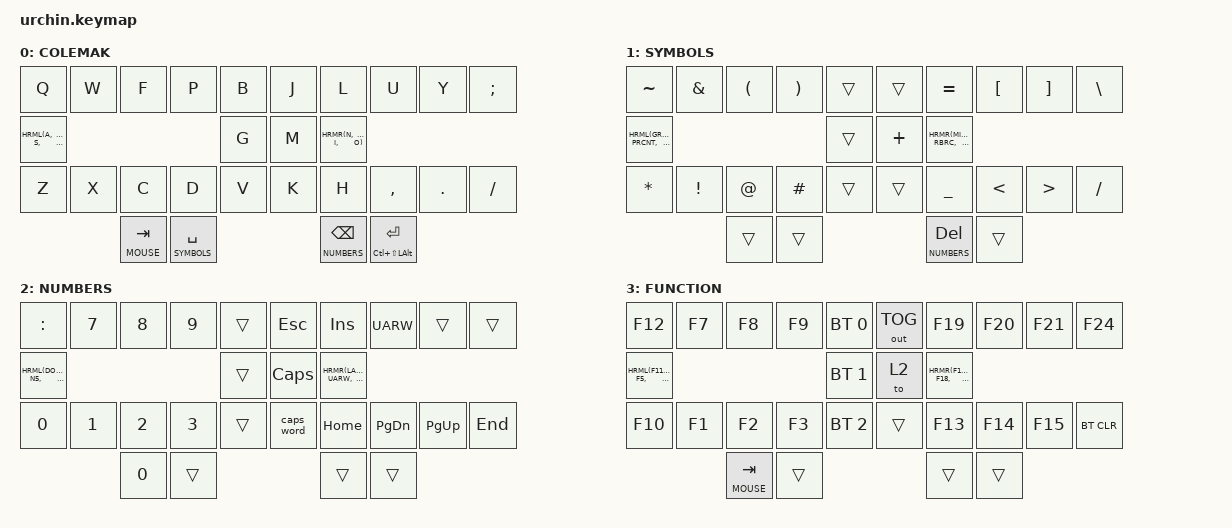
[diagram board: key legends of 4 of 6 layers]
// TODO
// add macro to accelerate or teleport mouse in each directions

#include <behaviors.dtsi>
#include <dt-bindings/zmk/keys.h>
#include <dt-bindings/zmk/bt.h>
#include <dt-bindings/zmk/outputs.h>

#include <dt-bindings/zmk/mouse.h> 
#include <behaviors.dtsi>

// Home row mods macro
#define HRML(k1,k2,k3,k4) &ht LSHFT k1  &ht LCTRL k2  &ht LALT k3  &ht LGUI k4
#define HRMR(k1,k2,k3,k4) &ht RGUI k1  &ht RALT k2  &ht RCTRL k3  &ht RSHFT k4

#define COLEMAK 0
#define SYMBOLS 1
#define NUMBERS 2
#define FUNCTIONS 3
#define MOUSE 4
#define GAME 5

#define U_MOUSE_MOVE_MAX 2000                     /* <--- New max speed setting (default: 600) */
#undef MOVE_UP
#undef MOVE_DOWN
#undef MOVE_LEFT
#undef MOVE_RIGHT
#define MOVE_UP MOVE_Y(-U_MOUSE_MOVE_MAX)
#define MOVE_DOWN MOVE_Y(U_MOUSE_MOVE_MAX)
#define MOVE_LEFT MOVE_X(-U_MOUSE_MOVE_MAX)
#define MOVE_RIGHT MOVE_X(U_MOUSE_MOVE_MAX)

&mmv {
 	time-to-max-speed-ms = <500>;             /* <--- How long time until max speed is reached (default: 500) */
};

#define U_MOUSE_SCROLL_MAX 100                    /* <--- New max speed setting (default: 10) */

#undef SCROLL_UP
#undef SCROLL_DOWN
#undef SCROLL_LEFT
#undef SCROLL_RIGHT
#define SCROLL_UP SCROLL_Y(U_MOUSE_SCROLL_MAX)
#define SCROLL_DOWN SCROLL_Y(-U_MOUSE_SCROLL_MAX)
#define SCROLL_LEFT SCROLL_X(-U_MOUSE_SCROLL_MAX)
#define SCROLL_RIGHT SCROLL_X(U_MOUSE_SCROLL_MAX)

&msc {
  time-to-max-speed-ms = <500>;                 /* <--- How long time until max speed is reached */
};

/ {
    behaviors {
        //ht: hold_tap {
        //    compatible = "zmk,behavior-hold-tap";
        //    #binding-cells = <2>;
        //    flavor = "balanced";
        //    tapping-term-ms = <220>;
        //    quick-tap-ms = <150>;
        //    require-prior-idle-ms = <100>;
        //    bindings = <&kp>, <&kp>;
        //};

        ht: hold_tap {
            compatible = "zmk,behavior-hold-tap";
            #binding-cells = <2>;
            flavor = "tap-preferred";
            tapping-term-ms = <180>;
            quick-tap-ms = <180>;
            require-prior-idle-ms = <100>;
            bindings = <&kp>, <&kp>;
        };

        //ht: hold_tap {
        //    compatible = "zmk,behavior-hold-tap";
        //    #binding-cells = <2>;
        //    flavor = "tap-unless-interrupted";
        //    tapping-term-ms = <200>;
        //    quick-tap-ms = <150>;
        //    require-prior-idle-ms = <100>;
        //    bindings = <&kp>, <&kp>;
        //};

    };

    combos {
        compatible = "zmk,combos"; 

        function_layer_combo {
            bindings = <&mo FUNCTIONS>;
            key-positions = <30 33>; //inner thumb keys
            timeout-ms = <50>;
        };

        game_layer_combo {
            bindings = <&tog GAME>;
            key-positions = <0 1 2 3>;
            timeout-ms = <50>;
        };

        repeat_key_combo_right {
            bindings = <&key_repeat>;
            key-positions = <26 27>; //bottom right index and middle finger keys
            timeout-ms = <50>;
        };

        repeat_key_combo_left {
            bindings = <&key_repeat>;
            key-positions = <22 23>; //bottom right index and middle finger keys
            timeout-ms = <50>;
        };

    };

    conditional_layers {
        compatible = "zmk,conditional-layers";
        tri_layer {
            if-layers = <SYMBOLS NUMBERS>;
            then-layer = <FUNCTIONS>;
        };
    };

    ZMK_MACRO(hyper_key,
        wait-ms = <0>;
        tap-ms = <40>;
        bindings = <&kp LSHFT &kp LCTRL &kp LALT &kp LGUI>;
    )

    keymap {
        compatible = "zmk,keymap";
        colemak_layer {
            label = "COLEMAK";
            bindings = <
        //╭──────────┬──────────┬──────────┬──────────┬──────────╮   ╭──────────┬──────────┬──────────┬──────────┬──────────╮
        //│  Q       │  W       │  F       │  P       │  B       │   │  J       │  L       │  U       │  Y       │  ; :     │
            &kp Q      &kp W      &kp F      &kp P      &kp B          &kp J      &kp L      &kp U      &kp Y      &kp SEMI
        //├──────────┼──────────┼──────────┼──────────┼──────────┤   ├──────────┼──────────┼──────────┼──────────┼──────────┤
        //│  A       │  R       │  S       │  T       │  G       │   │  M       │  N       │  E       │  I       │  O       │
            HRML(A,        R,         S,         T)     &kp G          &kp M      HRMR(N,        E,         I,        O)
        //├──────────┼──────────┼──────────┼──────────┼──────────┤   ├──────────┼──────────┼──────────┼──────────┼──────────┤
        //│  Z       │  X       │  C       │  D       │  V       │   │  K       │  H       │ , <      │ . >      │ / ?      │
            &kp Z      &kp X      &kp C      &kp D      &kp V          &kp K      &kp H      &kp COMMA  &kp DOT    &kp FSLH
        //╰──────────┴──────────┴──────────┼──────────┼──────────┤   ├──────────┼──────────┼──────────┴──────────┴──────────╯
                                  &lt MOUSE TAB   &lt SYMBOLS SPACE    &lt NUMBERS BSPC    &mt LC(LS(LALT)) ENTER 
        //                                 ╰──────────┴──────────╯   ╰──────────┴──────────╯
            >;
        };
        left_layer {
            label = "SYMBOLS";
            bindings = <
        //╭──────────┬──────────┬──────────┬──────────┬──────────╮   ╭──────────┬──────────┬──────────┬──────────┬──────────╮
        //│  ~       │  &       │  (       │  )       │          │   │          │  = +     │  [       │  ]       │  \ │     │
            &kp TILDE  &kp AMPS   &kp LPAR   &kp RPAR   &trans         &trans     &kp EQUAL  &kp LBKT   &kp RBKT   &kp BSLH
        //├──────────┼──────────┼──────────┼──────────┼──────────┤   ├──────────┼──────────┼──────────┼──────────┼──────────┤
        //│  `       │  $       │  %       │  ^       │          │   │          │ - _      │  {       │   }      │  ' "     │
            HRML(GRAVE, DLLR,      PRCNT,     CARET)    &trans         &kp PLUS  HRMR(MINUS, LBRC,      RBRC,       SQT)
        //├──────────┼──────────┼──────────┼──────────┼──────────┤   ├──────────┼──────────┼──────────┼──────────┼──────────┤
        //│  *       │ !        │  @       │  #       │          │   │          │  _       │  <       │  >       │  / ?     │
            &kp STAR   &kp EXCL   &kp AT     &kp HASH   &trans         &trans     &kp UNDER  &kp LT     &kp GT     &kp FSLH
        //╰──────────┴──────────┴──────────┼──────────┼──────────┤   ├──────────┼──────────┼──────────┴──────────┴──────────╯
                                            &trans     &trans        &lt NUMBERS DEL    &trans
        //                                 ╰──────────┴──────────╯   ╰──────────┴──────────╯
            >;
        };
		right_layer {
            label = "NUMBERS";
            bindings = <
        //╭──────────┬──────────┬──────────┬──────────┬──────────╮   ╭──────────┬──────────┬──────────┬──────────┬──────────╮
        //│  :       │  7       │  8       │  9       │          │   │ ESC      │ INSERT   │ UP       │          │          │
           &kp COLON   &kp N7     &kp N8     &kp N9     &trans         &kp ESC    &kp INS    &kp UARW    &trans     &trans     
        //├──────────┼──────────┼──────────┼──────────┼──────────┤   ├──────────┼──────────┼──────────┼──────────┼──────────┤
        //│  .       │  4       │  5       │  6       │          │   │ CAPS     │  LEFT    │ DOWN     │ UP       │          │
            HRML(DOT,   N4,        N5,        N6)       &trans         &kp CAPS   HRMR(LARW,  DARW,      UARW,      RARW)
        //├──────────┼──────────┼──────────┼──────────┼──────────┤   ├──────────┼──────────┼──────────┼──────────┼──────────┤
        //│  0       │  1       │  2       │  3       │          │   │ CAPS WRD │  HOME    │ PAGE DN  │ PAGE UP  │ END      │ 
             &kp N0    &kp N1     &kp N2     &kp N3     &trans        &caps_word  &kp HOME  &kp PG_DN   &kp PG_UP  &kp END
        //╰──────────┴──────────┴──────────┼──────────┼──────────┤   ├──────────┼──────────┼──────────┴──────────┴──────────╯
                                             &kp N0     &trans         &trans     &trans
        //                                 ╰──────────┴──────────╯   ╰──────────┴──────────╯
            >;
        };
        tri_layer {
            label = "FUNCTION";
            bindings = <
        //╭──────────┬──────────┬──────────┬──────────┬──────────╮   ╭──────────┬──────────┬──────────┬──────────┬──────────╮
        //           |          |          |          |          |   |          | FR       │ Open Mus │ Ply/Paus │ FF       │
        //│          │          │          │          │PROFILE 0 │   │          │          │          │          │          │
            &kp F12    &kp F7     &kp F8     &kp F9    &bt BT_SEL 0   &out OUT_TOG &kp F19    &kp F20    &kp F21    &kp F24
        //├──────────┼──────────┼──────────┼──────────┼──────────┤   ├──────────┼──────────┼──────────┼──────────┼──────────┤
        //           |          │          │          │PROFILE 1 │   │          │          │          |          │          │
           HRML(F11,    F4,        F5,        F6)      &bt BT_SEL 1    &to 2      HRMR(F16,   F17,        F18,       F23)
        //├──────────┼──────────┼──────────┼──────────┼──────────┤   ├──────────┼──────────┼──────────┼──────────┼──────────┤
        //|          │          │          │          │PROFILE 2 │   │          │          │          │          │          │
            &kp F10    &kp F1     &kp F2     &kp F3    &bt BT_SEL 2    &trans     &kp F13    &kp F14    &kp F15    &bt BT_CLR
        //╰──────────┴──────────┴──────────┼──────────┼──────────┤   ├──────────┼──────────┼──────────┴──────────┴──────────╯
                                        &lt MOUSE TAB    &trans         &trans     &trans
        //                                 ╰──────────┴──────────╯   ╰──────────┴──────────╯
            >;
        };

        mouse_layer {
            label = "MOUSE";
            bindings = <
        //╭──────────┬──────────┬──────────┬──────────┬──────────╮   ╭──────────┬──────────┬──────────┬──────────┬──────────╮
        //              mouse 4   mouse 5                                                       up          
           &trans      &mkp MB4   &mkp MB5   &trans    &trans           &trans     &trans   &mmv MOVE_UP &trans    &trans 
        //├──────────┼──────────┼──────────┼──────────┼──────────┤   ├──────────┼──────────┼──────────┼──────────┼──────────┤
        //             R click   Mid click   L click                                left       down      right
            &kp LSHFT &mkp MB2   &mkp MB3   &mkp MB1   &trans         &trans &mmv MOVE_LEFT &mmv MOVE_DOWN   &mmv MOVE_RIGHT  &trans
        //├──────────┼──────────┼──────────┼──────────┼──────────┤   ├──────────┼──────────┼──────────┼──────────┼──────────┤
        //                                                                        scroll R  scroll up  scroll dwn  scroll L   
            &trans     &trans     &trans     &trans     &trans        &trans  &msc SCRL_RIGHT &msc SCRL_UP &msc SCRL_DOWN  &msc SCRL_LEFT
        //╰──────────┴──────────┴──────────┼──────────┼──────────┤   ├──────────┼──────────┼──────────┴──────────┴──────────╯
        //                                               -----          ------
                                             &trans     &trans          &trans     &trans
        //                                 ╰──────────┴──────────╯   ╰──────────┴──────────╯
            >;
        };

        game_layer {
            label = "GAME";
            bindings = <
        //╭──────────┬──────────┬──────────┬──────────┬──────────╮   ╭──────────┬──────────┬──────────┬──────────┬──────────╮
        //│  Esc     │  Q       │  W       │  E       │  R       │   │  T       │  Y       │  U       │  I       │  O       │
            &kp ESC    &kp Q      &kp W      &kp E      &kp R          &kp T      &kp Y      &kp U      &kp I      &kp O
        //├──────────┼──────────┼──────────┼──────────┼──────────┤   ├──────────┼──────────┼──────────┼──────────┼──────────┤
        //│  Shft    │  A       │  S       │  D       │  F       │   │  G       │  H       │  J       │  K       │  L       │
            &kp LSHFT    &kp A     &kp S      &kp D      &kp F          &kp G      &kp H      &kp J      &kp K      &kp L
        //├──────────┼──────────┼──────────┼──────────┼──────────┤   ├──────────┼──────────┼──────────┼──────────┼──────────┤
        //│  Ctl     │  Z       │  X       │  C       │  V       │   │  B       │  N       │ M        │ P        │ Caps     │
            &kp LCTRL  &kp Z      &kp X      &kp C      &kp V          &kp B      &kp N      &kp M      &kp P      &kp CAPS
        //╰──────────┴──────────┴──────────┼──────────┼──────────┤   ├──────────┼──────────┼──────────┴──────────┴──────────╯
                                             &kp TAB   &kp SPACE      &kp BSPC  &kp ENTER 
        //                                 ╰──────────┴──────────╯   ╰──────────┴──────────╯
            >;
        };

        // Macros using meh key Work
        //╭──────────┬──────────┬──────────┬──────────┬──────────╮   ╭──────────┬──────────┬──────────┬──────────┬──────────╮
        //│ DevToys  │ ITerm    │ VSCode   │ IDEA     │ Brig Up  │   │ Vol Up   │ app left │ App min  │ App full │ app rght │
        //├──────────┼──────────┼──────────┼──────────┼──────────┤   ├──────────┼──────────┼──────────┼──────────┼──────────┤
        //  Teams    | Outlook  │ Reminders│ Obsidian │ Brig Dwn │   │ Vol Dwn  │ Lft Spc  │ App View | Spaces   │ Rgt Spc  │
        //├──────────┼──────────┼──────────┼──────────┼──────────┤   ├──────────┼──────────┼──────────┼──────────┼──────────┤
        //| KeyMap   │          │ Browser  │ Keepass  │ Lock Scr │   │ Mute     │ Mute Tms │ Scrn dn  │ Scrn up  │ Scrn sht │
        //╰──────────┴──────────┴──────────┼──────────┼──────────┤   ├──────────┼──────────┼──────────┴──────────┴──────────╯
        //                                 | Paste    |          |   |          | -------- |
        //                                 ╰──────────┴──────────╯   ╰──────────┴──────────╯

        // Macros using meh key Personal
        //╭──────────┬──────────┬──────────┬──────────┬──────────╮   ╭──────────┬──────────┬──────────┬──────────┬──────────╮
        //│ DevToys  │ ITerm    │          │ IDE      │ Brig Up  │   │ Vol Up   │ app left │ App min  │ App full │ app rght │
        //├──────────┼──────────┼──────────┼──────────┼──────────┤   ├──────────┼──────────┼──────────┼──────────┼──────────┤
        //  Calendar | Mail     | Reminders│ Obsidian │ Brig Dwn │   │ Vol Dwn  │ Lft Spc  │ App View | Spaces   │ Rgt Spc  │
        //├──────────┼──────────┼──────────┼──────────┼──────────┤   ├──────────┼──────────┼──────────┼──────────┼──────────┤
        //|          │ NordPass │ ChatGPT  │ Browser  │ Lock Scr │   │ Mute     │          │ Scrsht c │ Scrsht d │ KeyMap   │
        //╰──────────┴──────────┴──────────┼──────────┼──────────┤   ├──────────┼──────────┼──────────┴──────────┴──────────╯
        //                                 | Macro nm |          |   |          | -------- |
        //                                 ╰──────────┴──────────╯   ╰──────────┴──────────╯
    };
};
